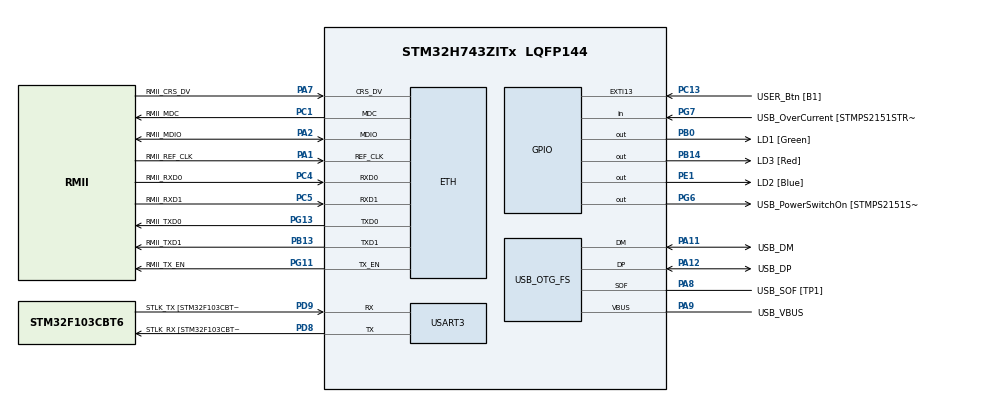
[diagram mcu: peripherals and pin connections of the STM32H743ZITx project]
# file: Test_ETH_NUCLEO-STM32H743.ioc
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CORTEX_M7.AccessPermission-Cortex_Memory_Protection_Unit_Region0_Settings=MPU_REGION_FULL_ACCESS
CORTEX_M7.AccessPermission-Cortex_Memory_Protection_Unit_Region1_Settings=MPU_REGION_FULL_ACCESS
CORTEX_M7.AccessPermission-Cortex_Memory_Protection_Unit_Region2_Settings=MPU_REGION_FULL_ACCESS
CORTEX_M7.BaseAddress-Cortex_Memory_Protection_Unit_Region0_Settings=0x30040000
CORTEX_M7.BaseAddress-Cortex_Memory_Protection_Unit_Region1_Settings=0x30044000
CORTEX_M7.BaseAddress-Cortex_Memory_Protection_Unit_Region2_Settings=0x30040000
CORTEX_M7.CPU_DCache=Enabled
CORTEX_M7.CPU_ICache=Enabled
CORTEX_M7.DisableExec-Cortex_Memory_Protection_Unit_Region0_Settings=MPU_INSTRUCTION_ACCESS_ENABLE
CORTEX_M7.DisableExec-Cortex_Memory_Protection_Unit_Region1_Settings=MPU_INSTRUCTION_ACCESS_ENABLE
CORTEX_M7.Enable-Cortex_Memory_Protection_Unit_Region0_Settings=MPU_REGION_ENABLE
CORTEX_M7.Enable-Cortex_Memory_Protection_Unit_Region1_Settings=MPU_REGION_ENABLE
CORTEX_M7.Enable-Cortex_Memory_Protection_Unit_Region2_Settings=MPU_REGION_ENABLE
CORTEX_M7.IsBufferable-Cortex_Memory_Protection_Unit_Region0_Settings=MPU_ACCESS_NOT_BUFFERABLE
CORTEX_M7.IsBufferable-Cortex_Memory_Protection_Unit_Region1_Settings=MPU_ACCESS_NOT_BUFFERABLE
CORTEX_M7.IsBufferable-Cortex_Memory_Protection_Unit_Region2_Settings=MPU_ACCESS_BUFFERABLE
CORTEX_M7.IsCacheable-Cortex_Memory_Protection_Unit_Region1_Settings=MPU_ACCESS_CACHEABLE
CORTEX_M7.IsShareable-Cortex_Memory_Protection_Unit_Region0_Settings=MPU_ACCESS_NOT_SHAREABLE
CORTEX_M7.IsShareable-Cortex_Memory_Protection_Unit_Region1_Settings=MPU_ACCESS_NOT_SHAREABLE
CORTEX_M7.MPU_Control=MPU_PRIVILEGED_DEFAULT
CORTEX_M7.Size-Cortex_Memory_Protection_Unit_Region0_Settings=MPU_REGION_SIZE_16KB
CORTEX_M7.Size-Cortex_Memory_Protection_Unit_Region1_Settings=MPU_REGION_SIZE_16KB
CORTEX_M7.Size-Cortex_Memory_Protection_Unit_Region2_Settings=MPU_REGION_SIZE_256B
CORTEX_M7.TypeExtField-Cortex_Memory_Protection_Unit_Region0_Settings=MPU_TEX_LEVEL1
ETH.MediaInterface=HAL_ETH_RMII_MODE
FREERTOS.Tasks01=defaultTask,0,256,StartDefaultTask,Default,NULL,Dynamic,NULL,NULL
LWIP.BSP.number=1
LWIP.IP_ADDRESS=192.168.008.077
LWIP.LWIP_DHCP=0
LWIP.MEM_SIZE=16360
LWIP.NETMASK_ADDRESS=255.255.255.000
LWIP.Version=v2.1.2_Cube
LWIP0.BSP.STBoard=false
LWIP0.BSP.api=BSP_COMPONENT_DRIVER
LWIP0.BSP.component=LAN8742
LWIP0.BSP.i2caddr=0
LWIP0.BSP.instance=LAN8742
LWIP0.BSP.name=Driver_PHY
LWIP0.BSP.solution=LAN8742
Mcu.Family=STM32H7
Mcu.Name=STM32H743ZITx
Mcu.Package=LQFP144
NVIC.ETH_IRQn=true\:5\:0\:false\:false\:true\:true\:true\:true
NVIC.PriorityGroup=NVIC_PRIORITYGROUP_4
NVIC.TIM6_DAC_IRQn=true\:0\:0\:false\:false\:true\:false\:false\:true
NVIC.TimeBase=TIM6_DAC_IRQn
NVIC.TimeBaseIP=TIM6
PA1.GPIO_Label=RMII_REF_CLK
PA1.GPIO_Speed=GPIO_SPEED_FREQ_VERY_HIGH
PA1.Mode=RMII
PA1.Signal=ETH_REF_CLK
PA10.GPIO_Label=USB_ID
PA10.Signal=USB_OTG_FS_ID
PA11.GPIO_Label=USB_DM
PA11.Mode=Device_Only
PA11.Signal=USB_OTG_FS_DM
PA12.GPIO_Label=USB_DP
PA12.Mode=Device_Only
PA12.Signal=USB_OTG_FS_DP
PA2.GPIO_Label=RMII_MDIO
PA2.GPIO_Speed=GPIO_SPEED_FREQ_VERY_HIGH
PA2.Mode=RMII
PA2.Signal=ETH_MDIO
PA7.GPIO_Label=RMII_CRS_DV
PA7.GPIO_Speed=GPIO_SPEED_FREQ_VERY_HIGH
PA7.Mode=RMII
PA7.Signal=ETH_CRS_DV
PA8.GPIO_Label=USB_SOF [TP1]
PA8.Mode=Activate_SOF_FS
PA8.Signal=USB_OTG_FS_SOF
PA9.GPIO_Label=USB_VBUS
PA9.Mode=Activate_VBUS
PA9.Signal=USB_OTG_FS_VBUS
PB0.GPIO_Label=LD1 [Green]
PB0.Signal=GPIO_Output
PB13.GPIO_Label=RMII_TXD1
PB13.GPIO_Speed=GPIO_SPEED_FREQ_VERY_HIGH
PB13.Mode=RMII
PB13.Signal=ETH_TXD1
PB14.GPIO_Label=LD3 [Red]
PB14.Signal=GPIO_Output
PC1.GPIO_Label=RMII_MDC
PC1.GPIO_Speed=GPIO_SPEED_FREQ_VERY_HIGH
PC1.Mode=RMII
PC1.Signal=ETH_MDC
PC13.GPIO_Label=USER_Btn [B1]
PC13.Signal=GPXTI13
PC14-OSC32_IN\ (OSC32_IN).Mode=LSE-External-Oscillator
PC14-OSC32_IN\ (OSC32_IN).Signal=RCC_OSC32_IN
PC15-OSC32_OUT\ (OSC32_OUT).Mode=LSE-External-Oscillator
PC15-OSC32_OUT\ (OSC32_OUT).Signal=RCC_OSC32_OUT
PC4.GPIO_Label=RMII_RXD0
PC4.GPIO_Speed=GPIO_SPEED_FREQ_VERY_HIGH
PC4.Mode=RMII
PC4.Signal=ETH_RXD0
PC5.GPIO_Label=RMII_RXD1
PC5.GPIO_Speed=GPIO_SPEED_FREQ_VERY_HIGH
PC5.Mode=RMII
PC5.Signal=ETH_RXD1
PD8.GPIO_Label=STLK_RX [STM32F103CBT6_PA3]
PD8.Mode=Asynchronous
PD8.Signal=USART3_TX
PD9.GPIO_Label=STLK_TX [STM32F103CBT6_PA2]
PD9.Mode=Asynchronous
PD9.Signal=USART3_RX
PE1.GPIO_Label=LD2 [Blue]
PE1.Signal=GPIO_Output
PG11.GPIO_Label=RMII_TX_EN
PG11.GPIO_Speed=GPIO_SPEED_FREQ_VERY_HIGH
PG11.Mode=RMII
PG11.Signal=ETH_TX_EN
PG13.GPIO_Label=RMII_TXD0
PG13.GPIO_Speed=GPIO_SPEED_FREQ_VERY_HIGH
PG13.Mode=RMII
PG13.Signal=ETH_TXD0
PG6.GPIO_Label=USB_PowerSwitchOn [STMPS2151STR_EN]
PG6.Signal=GPIO_Output
PG7.GPIO_Label=USB_OverCurrent [STMPS2151STR_FAULT]
PG7.Signal=GPIO_Input
PH0-OSC_IN\ (PH0).GPIO_Label=MCO
PH0-OSC_IN\ (PH0).Mode=HSE-External-Clock-Source
PH0-OSC_IN\ (PH0).Signal=RCC_OSC_IN
PH1-OSC_OUT\ (PH1).Signal=RCC_OSC_OUT
ProjectManager.HeapSize=0x200
ProjectManager.StackSize=0x400
ProjectManager.TargetToolchain=STM32CubeIDE
RCC.48MHZClocksFreq_Value=24000000
RCC.ADCFreq_Value=16125000
RCC.AHBFreq_Value=216000000
RCC.APB1CLKDivider=RCC_HCLK_DIV4
RCC.APB1Freq_Value=100000000
RCC.APB1TimFreq_Value=108000000
RCC.APB2CLKDivider=RCC_HCLK_DIV2
RCC.APB2Freq_Value=100000000
RCC.APB2TimFreq_Value=216000000
RCC.APB3Freq_Value=100000000
RCC.APB4Freq_Value=100000000
RCC.CortexFreq_Value=400000000
RCC.D1PPRE=RCC_APB3_DIV2
RCC.D2PPRE1=RCC_APB1_DIV2
RCC.D2PPRE2=RCC_APB2_DIV2
RCC.D3PPRE=RCC_APB4_DIV2
RCC.DIVM1=1
RCC.DIVN1=100
RCC.DIVQ1=13
RCC.HCLKFreq_Value=200000000
RCC.HPRE=RCC_HCLK_DIV2
RCC.HSE_VALUE=8000000
RCC.HSI_VALUE=64000000
RCC.PLLFRACN=0
RCC.PLLM=25
RCC.PLLMUL=RCC_PLL_MUL9
RCC.PLLN=432
RCC.PLLQ=9
RCC.PRESCALERUSB=RCC_USBCLKSOURCE_PLL_DIV1_5
RCC.PWR_Regulator_Voltage_Scale=PWR_REGULATOR_VOLTAGE_SCALE1
RCC.SYSCLKFreq_VALUE=400000000
RCC.SYSCLKSource=RCC_SYSCLKSOURCE_PLLCLK
RCC.SYSCLKSourceVirtual=RCC_SYSCLKSOURCE_PLLCLK
RCC.USBFreq_Value=61538461.538461536
RCC.VCOOutputFreq_Value=432000000
USART3.VirtualMode-Asynchronous=VM_ASYNC
USB_OTG_FS.VirtualMode=Device_Only
VP_FREERTOS_VS_CMSIS_V1.Mode=CMSIS_V1
VP_LWIP_VS_Enabled.Mode=Enabled
VP_SYS_VS_tim6.Mode=TIM6
board=NUCLEO-H743ZI

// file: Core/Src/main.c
/* USER CODE BEGIN Header */
/**
  ******************************************************************************
  * @file           : main.c
  * @brief          : Main program body
  ******************************************************************************
  * @attention
  *
  * <h2><center>&copy; Copyright (c) 2021 STMicroelectronics.
  * All rights reserved.</center></h2>
  *
  * This software component is licensed by ST under Ultimate Liberty license
  * SLA0044, the "License"; You may not use this file except in compliance with
  * the License. You may obtain a copy of the License at:
  *                             www.st.com/SLA0044
  *
  ******************************************************************************
  */
/* USER CODE END Header */
#include "main.h"
#include "cmsis_os.h"
#include "lwip.h"

/* USER CODE BEGIN Includes */
#include "tcp_echoserver.h"

/* USER CODE END Includes */

UART_HandleTypeDef huart3;

PCD_HandleTypeDef hpcd_USB_OTG_FS;

osThreadId defaultTaskHandle;

void SystemClock_Config(void);
static void MPU_Config(void);
static void MX_GPIO_Init(void);
static void MX_USART3_UART_Init(void);
static void MX_USB_OTG_FS_PCD_Init(void);
void StartDefaultTask(void const * argument);

int main(void)
{

  /* MPU Configuration--------------------------------------------------------*/
  MPU_Config();

  /* Enable I-Cache---------------------------------------------------------*/
  SCB_EnableICache();

  /* Enable D-Cache---------------------------------------------------------*/
  SCB_EnableDCache();

  /* MCU Configuration--------------------------------------------------------*/

  /* Reset of all peripherals, Initializes the Flash interface and the Systick. */
  HAL_Init();

  /* Configure the system clock */
  SystemClock_Config();

  /* Initialize all configured peripherals */
  MX_GPIO_Init();
  MX_USART3_UART_Init();
  MX_USB_OTG_FS_PCD_Init();

  /* Create the thread(s) */
  /* definition and creation of defaultTask */
  osThreadDef(defaultTask, StartDefaultTask, osPriorityNormal, 0, 256);
  defaultTaskHandle = osThreadCreate(osThread(defaultTask), NULL);

  /* Start scheduler */
  osKernelStart();

  /* We should never get here as control is now taken by the scheduler */
  /* Infinite loop */
  while (1)
  {

  }
}

void SystemClock_Config(void)
{
  RCC_OscInitTypeDef RCC_OscInitStruct = {0};
  RCC_ClkInitTypeDef RCC_ClkInitStruct = {0};

  /** Supply configuration update enable
  */
  HAL_PWREx_ConfigSupply(PWR_LDO_SUPPLY);
  /** Configure the main internal regulator output voltage
  */
  __HAL_PWR_VOLTAGESCALING_CONFIG(PWR_REGULATOR_VOLTAGE_SCALE1);

  while(!__HAL_PWR_GET_FLAG(PWR_FLAG_VOSRDY)) {}
  /** Initializes the RCC Oscillators according to the specified parameters
  * in the RCC_OscInitTypeDef structure.
  */
  RCC_OscInitStruct.OscillatorType = RCC_OSCILLATORTYPE_HSE;
  RCC_OscInitStruct.HSEState = RCC_HSE_BYPASS;
  RCC_OscInitStruct.PLL.PLLState = RCC_PLL_ON;
  RCC_OscInitStruct.PLL.PLLSource = RCC_PLLSOURCE_HSE;
  RCC_OscInitStruct.PLL.PLLM = 1;
  RCC_OscInitStruct.PLL.PLLN = 100;
  RCC_OscInitStruct.PLL.PLLP = 2;
  RCC_OscInitStruct.PLL.PLLQ = 13;
  RCC_OscInitStruct.PLL.PLLR = 2;
  RCC_OscInitStruct.PLL.PLLRGE = RCC_PLL1VCIRANGE_3;
  RCC_OscInitStruct.PLL.PLLVCOSEL = RCC_PLL1VCOWIDE;
  RCC_OscInitStruct.PLL.PLLFRACN = 0;
  if (HAL_RCC_OscConfig(&RCC_OscInitStruct) != HAL_OK)
  {
    Error_Handler();
  }
  /** Initializes the CPU, AHB and APB buses clocks
  */
  RCC_ClkInitStruct.ClockType = RCC_CLOCKTYPE_HCLK|RCC_CLOCKTYPE_SYSCLK
                              |RCC_CLOCKTYPE_PCLK1|RCC_CLOCKTYPE_PCLK2
                              |RCC_CLOCKTYPE_D3PCLK1|RCC_CLOCKTYPE_D1PCLK1;
  RCC_ClkInitStruct.SYSCLKSource = RCC_SYSCLKSOURCE_PLLCLK;
  RCC_ClkInitStruct.SYSCLKDivider = RCC_SYSCLK_DIV1;
  RCC_ClkInitStruct.AHBCLKDivider = RCC_HCLK_DIV2;
  RCC_ClkInitStruct.APB3CLKDivider = RCC_APB3_DIV2;
  RCC_ClkInitStruct.APB1CLKDivider = RCC_APB1_DIV2;
  RCC_ClkInitStruct.APB2CLKDivider = RCC_APB2_DIV2;
  RCC_ClkInitStruct.APB4CLKDivider = RCC_APB4_DIV2;

  if (HAL_RCC_ClockConfig(&RCC_ClkInitStruct, FLASH_LATENCY_2) != HAL_OK)
  {
    Error_Handler();
  }
}

static void MX_USART3_UART_Init(void)
{

  huart3.Instance = USART3;
  huart3.Init.BaudRate = 115200;
  huart3.Init.WordLength = UART_WORDLENGTH_8B;
  huart3.Init.StopBits = UART_STOPBITS_1;
  huart3.Init.Parity = UART_PARITY_NONE;
  huart3.Init.Mode = UART_MODE_TX_RX;
  huart3.Init.HwFlowCtl = UART_HWCONTROL_NONE;
  huart3.Init.OverSampling = UART_OVERSAMPLING_16;
  huart3.Init.OneBitSampling = UART_ONE_BIT_SAMPLE_DISABLE;
  huart3.Init.ClockPrescaler = UART_PRESCALER_DIV1;
  huart3.AdvancedInit.AdvFeatureInit = UART_ADVFEATURE_NO_INIT;
  if (HAL_UART_Init(&huart3) != HAL_OK)
  {
    Error_Handler();
  }
  if (HAL_UARTEx_SetTxFifoThreshold(&huart3, UART_TXFIFO_THRESHOLD_1_8) != HAL_OK)
  {
    Error_Handler();
  }
  if (HAL_UARTEx_SetRxFifoThreshold(&huart3, UART_RXFIFO_THRESHOLD_1_8) != HAL_OK)
  {
    Error_Handler();
  }
  if (HAL_UARTEx_DisableFifoMode(&huart3) != HAL_OK)
  {
    Error_Handler();
  }

}

static void MX_USB_OTG_FS_PCD_Init(void)
{

  hpcd_USB_OTG_FS.Instance = USB_OTG_FS;
  hpcd_USB_OTG_FS.Init.dev_endpoints = 9;
  hpcd_USB_OTG_FS.Init.speed = PCD_SPEED_FULL;
  hpcd_USB_OTG_FS.Init.dma_enable = DISABLE;
  hpcd_USB_OTG_FS.Init.phy_itface = PCD_PHY_EMBEDDED;
  hpcd_USB_OTG_FS.Init.Sof_enable = ENABLE;
  hpcd_USB_OTG_FS.Init.low_power_enable = DISABLE;
  hpcd_USB_OTG_FS.Init.lpm_enable = DISABLE;
  hpcd_USB_OTG_FS.Init.battery_charging_enable = ENABLE;
  hpcd_USB_OTG_FS.Init.vbus_sensing_enable = ENABLE;
  hpcd_USB_OTG_FS.Init.use_dedicated_ep1 = DISABLE;
  if (HAL_PCD_Init(&hpcd_USB_OTG_FS) != HAL_OK)
  {
    Error_Handler();
  }

}

static void MX_GPIO_Init(void)
{
  GPIO_InitTypeDef GPIO_InitStruct = {0};

  /* GPIO Ports Clock Enable */
  __HAL_RCC_GPIOC_CLK_ENABLE();
  __HAL_RCC_GPIOH_CLK_ENABLE();
  __HAL_RCC_GPIOA_CLK_ENABLE();
  __HAL_RCC_GPIOB_CLK_ENABLE();
  __HAL_RCC_GPIOD_CLK_ENABLE();
  __HAL_RCC_GPIOG_CLK_ENABLE();
  __HAL_RCC_GPIOE_CLK_ENABLE();

  /*Configure GPIO pin Output Level */
  HAL_GPIO_WritePin(GPIOB, LD1_Pin|LD3_Pin, GPIO_PIN_RESET);

  /*Configure GPIO pin Output Level */
  HAL_GPIO_WritePin(USB_PowerSwitchOn_GPIO_Port, USB_PowerSwitchOn_Pin, GPIO_PIN_RESET);

  /*Configure GPIO pin Output Level */
  HAL_GPIO_WritePin(LD2_GPIO_Port, LD2_Pin, GPIO_PIN_RESET);

  /*Configure GPIO pin : USER_Btn_Pin */
  GPIO_InitStruct.Pin = USER_Btn_Pin;
  GPIO_InitStruct.Mode = GPIO_MODE_IT_RISING;
  GPIO_InitStruct.Pull = GPIO_NOPULL;
  HAL_GPIO_Init(USER_Btn_GPIO_Port, &GPIO_InitStruct);

  /*Configure GPIO pins : LD1_Pin LD3_Pin */
  GPIO_InitStruct.Pin = LD1_Pin|LD3_Pin;
  GPIO_InitStruct.Mode = GPIO_MODE_OUTPUT_PP;
  GPIO_InitStruct.Pull = GPIO_NOPULL;
  GPIO_InitStruct.Speed = GPIO_SPEED_FREQ_LOW;
  HAL_GPIO_Init(GPIOB, &GPIO_InitStruct);

  /*Configure GPIO pin : USB_PowerSwitchOn_Pin */
  GPIO_InitStruct.Pin = USB_PowerSwitchOn_Pin;
  GPIO_InitStruct.Mode = GPIO_MODE_OUTPUT_PP;
  GPIO_InitStruct.Pull = GPIO_NOPULL;
  GPIO_InitStruct.Speed = GPIO_SPEED_FREQ_LOW;
  HAL_GPIO_Init(USB_PowerSwitchOn_GPIO_Port, &GPIO_InitStruct);

  /*Configure GPIO pin : USB_OverCurrent_Pin */
  GPIO_InitStruct.Pin = USB_OverCurrent_Pin;
  GPIO_InitStruct.Mode = GPIO_MODE_INPUT;
  GPIO_InitStruct.Pull = GPIO_NOPULL;
  HAL_GPIO_Init(USB_OverCurrent_GPIO_Port, &GPIO_InitStruct);

  /*Configure GPIO pin : LD2_Pin */
  GPIO_InitStruct.Pin = LD2_Pin;
  GPIO_InitStruct.Mode = GPIO_MODE_OUTPUT_PP;
  GPIO_InitStruct.Pull = GPIO_NOPULL;
  GPIO_InitStruct.Speed = GPIO_SPEED_FREQ_LOW;
  HAL_GPIO_Init(LD2_GPIO_Port, &GPIO_InitStruct);

}

void StartDefaultTask(void const * argument)
{
  /* init code for LWIP */
  MX_LWIP_Init();
  /* USER CODE BEGIN 5 */
  /* Infinite loop */
  tcp_echoserver_init();

	/* Infinite loop */
	for (;;)
	{
	  osDelay(1000);
	  HAL_GPIO_TogglePin(LD1_GPIO_Port, LD1_Pin);
	}
  /* USER CODE END 5 */
}

/* MPU Configuration */

void MPU_Config(void)
{
  MPU_Region_InitTypeDef MPU_InitStruct = {0};

  /* Disables the MPU */
  HAL_MPU_Disable();
  /** Initializes and configures the Region and the memory to be protected
  */
  MPU_InitStruct.Enable = MPU_REGION_ENABLE;
  MPU_InitStruct.Number = MPU_REGION_NUMBER0;
  MPU_InitStruct.BaseAddress = 0x30040000;
  MPU_InitStruct.Size = MPU_REGION_SIZE_16KB;
  MPU_InitStruct.SubRegionDisable = 0x0;
  MPU_InitStruct.TypeExtField = MPU_TEX_LEVEL1;
  MPU_InitStruct.AccessPermission = MPU_REGION_FULL_ACCESS;
  MPU_InitStruct.DisableExec = MPU_INSTRUCTION_ACCESS_ENABLE;
  MPU_InitStruct.IsShareable = MPU_ACCESS_NOT_SHAREABLE;
  MPU_InitStruct.IsCacheable = MPU_ACCESS_NOT_CACHEABLE;
  MPU_InitStruct.IsBufferable = MPU_ACCESS_NOT_BUFFERABLE;

  HAL_MPU_ConfigRegion(&MPU_InitStruct);
  /** Initializes and configures the Region and the memory to be protected
  */
  MPU_InitStruct.Number = MPU_REGION_NUMBER1;
  MPU_InitStruct.BaseAddress = 0x30044000;
  MPU_InitStruct.TypeExtField = MPU_TEX_LEVEL0;
  MPU_InitStruct.IsCacheable = MPU_ACCESS_CACHEABLE;

  HAL_MPU_ConfigRegion(&MPU_InitStruct);
  /** Initializes and configures the Region and the memory to be protected
  */
  MPU_InitStruct.Number = MPU_REGION_NUMBER2;
  MPU_InitStruct.BaseAddress = 0x30040000;
  MPU_InitStruct.Size = MPU_REGION_SIZE_256B;
  MPU_InitStruct.IsCacheable = MPU_ACCESS_NOT_CACHEABLE;
  MPU_InitStruct.IsBufferable = MPU_ACCESS_BUFFERABLE;

  HAL_MPU_ConfigRegion(&MPU_InitStruct);
  /* Enables the MPU */
  HAL_MPU_Enable(MPU_PRIVILEGED_DEFAULT);

}
void HAL_TIM_PeriodElapsedCallback(TIM_HandleTypeDef *htim)
{
  if (htim->Instance == TIM6) {
    HAL_IncTick();
  }
}

void Error_Handler(void)
{
  __disable_irq();
  while (1)
  {
  }
}

/************************ (C) COPYRIGHT STMicroelectronics *****END OF FILE****/
